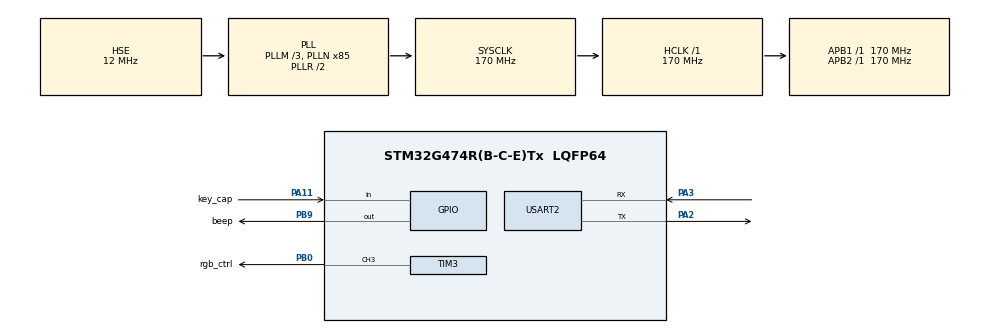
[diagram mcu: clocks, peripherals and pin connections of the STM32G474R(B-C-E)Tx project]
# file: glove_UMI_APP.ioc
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Dma.Request0=USART2_RX
Dma.Request1=USART2_TX
Dma.Request2=TIM3_CH3
Dma.USART2_RX.0.Direction=DMA_PERIPH_TO_MEMORY
Dma.USART2_RX.0.EventEnable=DISABLE
Dma.USART2_RX.0.Instance=DMA1_Channel2
Dma.USART2_RX.0.MemDataAlignment=DMA_MDATAALIGN_BYTE
Dma.USART2_RX.0.MemInc=DMA_MINC_ENABLE
Dma.USART2_RX.0.Mode=DMA_CIRCULAR
Dma.USART2_RX.0.PeriphDataAlignment=DMA_PDATAALIGN_BYTE
Dma.USART2_RX.0.PeriphInc=DMA_PINC_DISABLE
Dma.USART2_RX.0.Polarity=HAL_DMAMUX_REQ_GEN_RISING
Dma.USART2_RX.0.Priority=DMA_PRIORITY_HIGH
Dma.USART2_RX.0.RequestNumber=1
Dma.USART2_RX.0.SignalID=NONE
Dma.USART2_RX.0.SyncEnable=DISABLE
Dma.USART2_RX.0.SyncPolarity=HAL_DMAMUX_SYNC_NO_EVENT
Dma.USART2_RX.0.SyncRequestNumber=1
Dma.USART2_RX.0.SyncSignalID=NONE
Dma.USART2_TX.1.Direction=DMA_MEMORY_TO_PERIPH
Dma.USART2_TX.1.EventEnable=DISABLE
Dma.USART2_TX.1.Instance=DMA1_Channel3
Dma.USART2_TX.1.MemDataAlignment=DMA_MDATAALIGN_BYTE
Dma.USART2_TX.1.MemInc=DMA_MINC_ENABLE
Dma.USART2_TX.1.Mode=DMA_NORMAL
Dma.USART2_TX.1.PeriphDataAlignment=DMA_PDATAALIGN_BYTE
Dma.USART2_TX.1.PeriphInc=DMA_PINC_DISABLE
Dma.USART2_TX.1.Polarity=HAL_DMAMUX_REQ_GEN_RISING
Dma.USART2_TX.1.Priority=DMA_PRIORITY_HIGH
Dma.USART2_TX.1.RequestNumber=1
Dma.USART2_TX.1.SignalID=NONE
Dma.USART2_TX.1.SyncEnable=DISABLE
Dma.USART2_TX.1.SyncPolarity=HAL_DMAMUX_SYNC_NO_EVENT
Dma.USART2_TX.1.SyncRequestNumber=1
Dma.USART2_TX.1.SyncSignalID=NONE
Dma.TIM3_CH3.2.Direction=DMA_MEMORY_TO_PERIPH
Dma.TIM3_CH3.2.EventEnable=DISABLE
Dma.TIM3_CH3.2.Instance=DMA1_Channel1
Dma.TIM3_CH3.2.MemDataAlignment=DMA_MDATAALIGN_WORD
Dma.TIM3_CH3.2.MemInc=DMA_MINC_ENABLE
Dma.TIM3_CH3.2.Mode=DMA_NORMAL
Dma.TIM3_CH3.2.PeriphDataAlignment=DMA_PDATAALIGN_WORD
Dma.TIM3_CH3.2.PeriphInc=DMA_PINC_DISABLE
Dma.TIM3_CH3.2.Polarity=HAL_DMAMUX_REQ_GEN_RISING
Dma.TIM3_CH3.2.Priority=DMA_PRIORITY_VERY_HIGH
Dma.TIM3_CH3.2.RequestNumber=1
Dma.TIM3_CH3.2.SignalID=NONE
Dma.TIM3_CH3.2.SyncEnable=DISABLE
Dma.TIM3_CH3.2.SyncPolarity=HAL_DMAMUX_SYNC_NO_EVENT
Dma.TIM3_CH3.2.SyncRequestNumber=1
Dma.TIM3_CH3.2.SyncSignalID=NONE
Mcu.Family=STM32G4
Mcu.Name=STM32G474R(B-C-E)Tx
Mcu.Package=LQFP64
NVIC.DMA1_Channel1_IRQn=true\:6\:0\:true\:false\:true\:false\:true\:true
NVIC.DMA1_Channel2_IRQn=true\:6\:0\:true\:false\:true\:false\:true\:true
NVIC.DMA1_Channel3_IRQn=true\:6\:0\:true\:false\:true\:false\:true\:true
NVIC.PriorityGroup=NVIC_PRIORITYGROUP_4
NVIC.TIM1_UP_TIM16_IRQn=true\:15\:0\:false\:false\:true\:false\:true\:true
NVIC.TimeBase=TIM1_UP_TIM16_IRQn
NVIC.TimeBaseIP=TIM1
NVIC.USART2_IRQn=true\:6\:0\:true\:false\:true\:true\:true\:true
PA11.GPIO_Label=key_cap
PA11.GPIO_PuPd=GPIO_PULLUP
PA11.Signal=GPIO_Input
PA13.Mode=Serial_Wire
PA13.Signal=SYS_JTMS-SWDIO
PA14.Mode=Serial_Wire
PA14.Signal=SYS_JTCK-SWCLK
PA2.Mode=Asynchronous
PA2.Signal=USART2_TX
PA3.Mode=Asynchronous
PA3.Signal=USART2_RX
PB0.GPIO_Label=rgb_ctrl
PB0.GPIO_PuPd=GPIO_PULLDOWN
PB0.GPIO_Speed=GPIO_SPEED_FREQ_VERY_HIGH
PB0.Signal=S_TIM3_CH3
PB9.GPIO_Label=beep
PB9.GPIO_PuPd=GPIO_PULLUP
PB9.GPIO_Speed=GPIO_SPEED_FREQ_VERY_HIGH
PB9.PinState=GPIO_PIN_SET
PB9.Signal=GPIO_Output
PC14-OSC32_IN.Mode=LSE-External-Oscillator
PC14-OSC32_IN.Signal=RCC_OSC32_IN
PC15-OSC32_OUT.Mode=LSE-External-Oscillator
PC15-OSC32_OUT.Signal=RCC_OSC32_OUT
PF0-OSC_IN.Mode=HSE-External-Oscillator
PF0-OSC_IN.Signal=RCC_OSC_IN
PF1-OSC_OUT.Mode=HSE-External-Oscillator
PF1-OSC_OUT.Signal=RCC_OSC_OUT
ProjectManager.HeapSize=0x200
ProjectManager.StackSize=0x400
ProjectManager.TargetToolchain=CMake
RCC.ADC12Freq_Value=170000000
RCC.ADC345Freq_Value=170000000
RCC.AHBFreq_Value=170000000
RCC.APB1Freq_Value=170000000
RCC.APB1TimFreq_Value=170000000
RCC.APB2Freq_Value=170000000
RCC.APB2TimFreq_Value=170000000
RCC.CortexFreq_Value=170000000
RCC.EXTERNAL_CLOCK_VALUE=12288000
RCC.HCLKFreq_Value=170000000
RCC.HSE_VALUE=12000000
RCC.HSI48_VALUE=48000000
RCC.HSI_VALUE=16000000
RCC.PLLM=RCC_PLLM_DIV3
RCC.PLLN=85
RCC.PLLSourceVirtual=RCC_PLLSOURCE_HSE
RCC.RTCClockSelection=RCC_RTCCLKSOURCE_LSE
RCC.SYSCLKFreq_VALUE=170000000
RCC.SYSCLKSource=RCC_SYSCLKSOURCE_PLLCLK
RCC.USBFreq_Value=170000000
RCC.VCOOutputFreq_Value=340000000
RTC.Date=27
RTC.Hours=12
RTC.Month=RTC_MONTH_FEBRUARY
RTC.WeekDay=RTC_WEEKDAY_FRIDAY
RTC.Year=16
SH.S_TIM3_CH3.0=TIM3_CH3,PWM Generation3 CH3
TIM3.AutoReloadPreload=TIM_AUTORELOAD_PRELOAD_DISABLE
TIM3.Channel-PWM\ Generation3\ CH3=TIM_CHANNEL_3
TIM3.ClearInputSource=TIM_CLEARINPUTSOURCE_NONE
TIM3.ClockDivision=TIM_CLOCKDIVISION_DIV1
TIM3.CounterMode=TIM_COUNTERMODE_UP
TIM3.OCFastMode_PWM-PWM\ Generation3\ CH3=TIM_OCFAST_DISABLE
TIM3.OCMode_PWM-PWM\ Generation3\ CH3=TIM_OCMODE_PWM1
TIM3.OCPolarity_3=TIM_OCPOLARITY_HIGH
TIM3.Period=203
TIM3.Prescaler=0
TIM3.TIM_MasterOutputTrigger=TIM_TRGO_RESET
TIM3.TIM_MasterSlaveMode=TIM_MASTERSLAVEMODE_DISABLE
USART2.VirtualMode-Asynchronous=VM_ASYNC
VP_RTC_VS_RTC_Activate.Mode=RTC_Enabled
VP_RTC_VS_RTC_Calendar.Mode=RTC_Calendar
VP_SYS_VS_DBSignals.Mode=DisableDeadBatterySignals
VP_SYS_VS_tim1.Mode=TIM1
board=custom

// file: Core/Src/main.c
/* USER CODE BEGIN Header */
/**
  ******************************************************************************
  * @file           : main.c
  * @brief          : Main program body
  ******************************************************************************
  * @attention
  *
  * Copyright (c) 2026 STMicroelectronics.
  * All rights reserved.
  *
  * This software is licensed under terms that can be found in the LICENSE file
  * in the root directory of this software component.
  * If no LICENSE file comes with this software, it is provided AS-IS.
  *
  ******************************************************************************
  */
/* USER CODE END Header */
#include "main.h"
#include "dma.h"
#include "tim.h"
#include "rtc.h"
#include "usart.h"
#include "gpio.h"

/* USER CODE BEGIN Includes */
#include "FreeRTOS.h"
#include "task.h"
#include "task_manager.h"
#include "firmware_layout.h"
/* USER CODE END Includes */

void SystemClock_Config(void);

int main(void)
{

  /* USER CODE BEGIN 1 */

  /* Bootloader从APP1跳转时，应用必须先接管向量表和中断状态。 */
  SCB->VTOR = FIRMWARE_APP1_START_ADDRESS;
  __DSB();
  __ISB();
  __enable_irq();

  /* USER CODE END 1 */

  /* MCU Configuration--------------------------------------------------------*/

  /* Reset of all peripherals, Initializes the Flash interface and the Systick. */
  HAL_Init();

  /* Configure the system clock */
  SystemClock_Config();

  /* Initialize all configured peripherals */
  MX_GPIO_Init();
  MX_DMA_Init();
  MX_TIM3_Init();//用于LED的PWM输出
  MX_USART2_UART_Init();
  MX_RTC_Init();
  /* USER CODE BEGIN 2 */
  // bsp_beep_driver_init();
  // bsp_beep_driver_set(true);
  // HAL_Delay(1000);
  // bsp_beep_driver_set(false);

  if (TASK_OK != task_manager_init())
  {
    Error_Handler();
  }

  vTaskStartScheduler();
  Error_Handler();

  /* USER CODE END 2 */

  /* Infinite loop */
  while (1)
  {

  }
}

void SystemClock_Config(void)
{
  RCC_OscInitTypeDef RCC_OscInitStruct = {0};
  RCC_ClkInitTypeDef RCC_ClkInitStruct = {0};

  /** Configure the main internal regulator output voltage
  */
  HAL_PWREx_ControlVoltageScaling(PWR_REGULATOR_VOLTAGE_SCALE1_BOOST);

  /** Configure LSE Drive Capability
  */
  HAL_PWR_EnableBkUpAccess();
  __HAL_RCC_LSEDRIVE_CONFIG(RCC_LSEDRIVE_LOW);

  /** Initializes the RCC Oscillators according to the specified parameters
  * in the RCC_OscInitTypeDef structure.
  */
  RCC_OscInitStruct.OscillatorType = RCC_OSCILLATORTYPE_HSE|RCC_OSCILLATORTYPE_LSE;
  RCC_OscInitStruct.HSEState = RCC_HSE_ON;
  RCC_OscInitStruct.LSEState = RCC_LSE_ON;
  RCC_OscInitStruct.PLL.PLLState = RCC_PLL_ON;
  RCC_OscInitStruct.PLL.PLLSource = RCC_PLLSOURCE_HSE;
  RCC_OscInitStruct.PLL.PLLM = RCC_PLLM_DIV3;
  RCC_OscInitStruct.PLL.PLLN = 85;
  RCC_OscInitStruct.PLL.PLLP = RCC_PLLP_DIV2;
  RCC_OscInitStruct.PLL.PLLQ = RCC_PLLQ_DIV2;
  RCC_OscInitStruct.PLL.PLLR = RCC_PLLR_DIV2;
  if (HAL_RCC_OscConfig(&RCC_OscInitStruct) != HAL_OK)
  {
    Error_Handler();
  }

  /** Initializes the CPU, AHB and APB buses clocks
  */
  RCC_ClkInitStruct.ClockType = RCC_CLOCKTYPE_HCLK|RCC_CLOCKTYPE_SYSCLK
                              |RCC_CLOCKTYPE_PCLK1|RCC_CLOCKTYPE_PCLK2;
  RCC_ClkInitStruct.SYSCLKSource = RCC_SYSCLKSOURCE_PLLCLK;
  RCC_ClkInitStruct.AHBCLKDivider = RCC_SYSCLK_DIV1;
  RCC_ClkInitStruct.APB1CLKDivider = RCC_HCLK_DIV1;
  RCC_ClkInitStruct.APB2CLKDivider = RCC_HCLK_DIV1;

  if (HAL_RCC_ClockConfig(&RCC_ClkInitStruct, FLASH_LATENCY_4) != HAL_OK)
  {
    Error_Handler();
  }
}

void HAL_TIM_PeriodElapsedCallback(TIM_HandleTypeDef *htim)
{
  if (htim->Instance == TIM1)
  {
    HAL_IncTick();
  }
}

void Error_Handler(void)
{
  __disable_irq();
  while (1)
  {
  }
}
